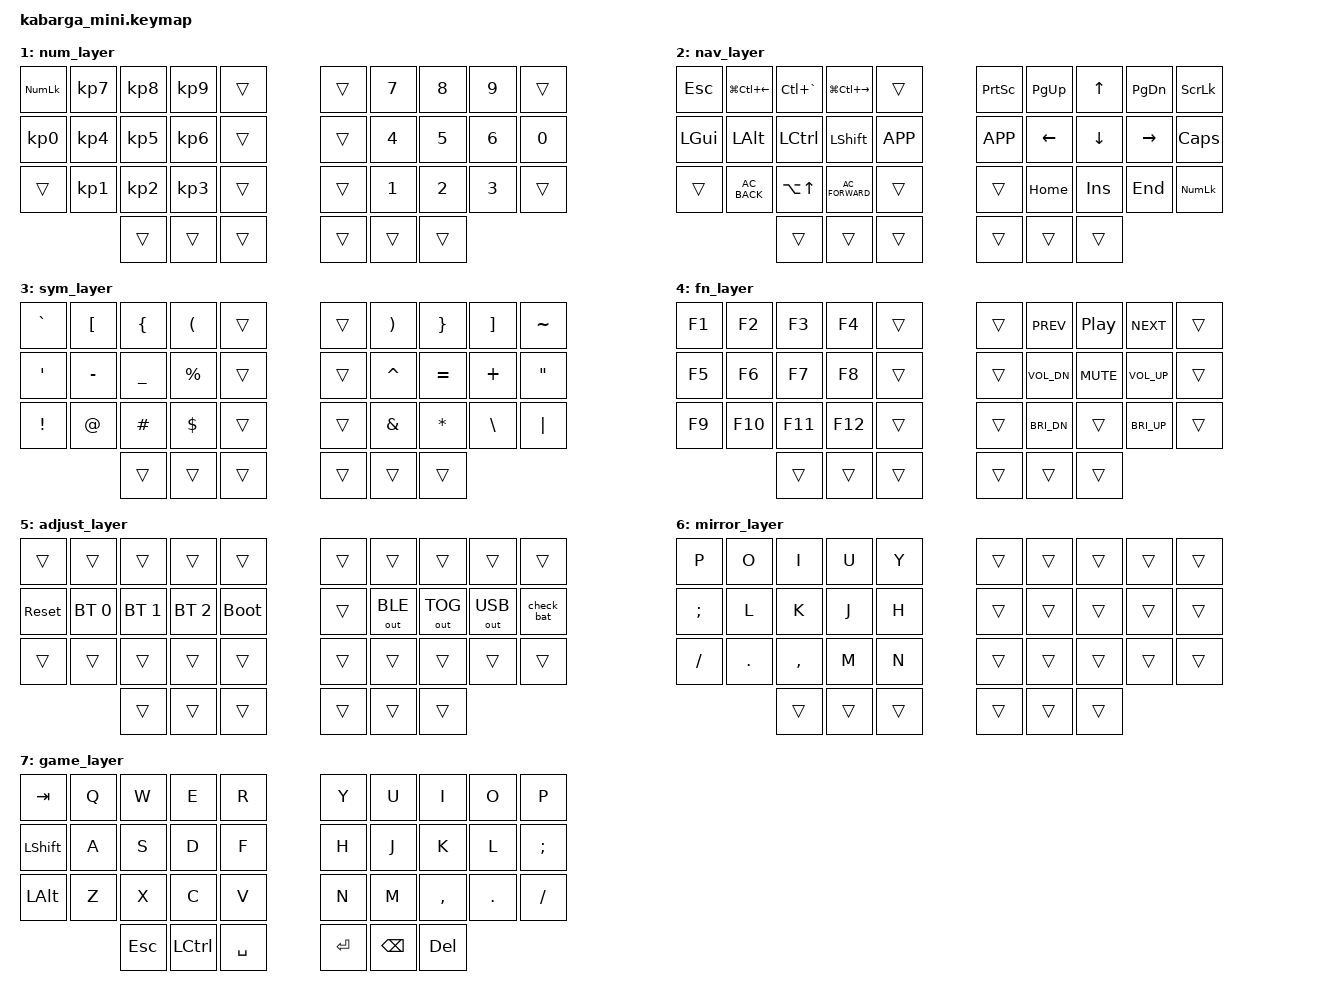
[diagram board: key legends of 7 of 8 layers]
/*
 * Copyright (c) 2020 The ZMK Contributors
 *
 * SPDX-License-Identifier: MIT
 */


#include <behaviors.dtsi>
#include <dt-bindings/zmk/keys.h>
#include <dt-bindings/zmk/bt.h>
#include <dt-bindings/zmk/outputs.h>
#include <dt-bindings/zmk/ext_power.h>
#include <dt-bindings/zmk/rgb.h>


#define HRML(k1,k2,k3,k4) &mt LGUI k1  &mt LALT k2  &mt LCTRL k3  &mt LSHFT k4
#define HRMR(k1,k2,k3,k4) &mt RSHFT k1  &mt RCTRL k2  &mt RALT k3  &mt RGUI k4
#define TERM &kp LC(GRAVE)
#define TASK_V &kp LG(TAB)
#define DESK_P &kp LG(LC(LEFT))
#define DESK_N &kp LG(LC(RIGHT))
#define COMBO(NAME, BINDINGS, KEYPOS, LAYERS) \
    combo_##NAME { \
        timeout-ms = <50>; \
        bindings = <BINDINGS>; \
        key-positions = <KEYPOS>; \
        layers = <LAYERS>; \
    };


&lt {
    flavor = "tap-preferred"; // balanced
    tapping-term-ms = <150>;
    quick-tap-ms = <200>;
};
&mt {
    flavor = "tap-preferred"; // balanced
    tapping-term-ms = <150>;
    quick-tap-ms = <200>;
};


/ {
    //╭──────┬──────┬──────┬──────┬──────╮   ╭──────┬──────┬──────┬──────┬──────╮
    //│  0   │  1   │  2   │  3   │  4   │   │  5   │  6   │  7   │  8   │  9   │
    //├──────┼──────┼──────┼──────┼──────┼───┼──────┼──────┼──────┼──────┼──────┤
    //│  10  │  11  │  12  │  13  │  14  │   │  15  │  16  │  17  │  18  │  19  │
    //├──────┼──────┼──────┼──────┼──────┤   ├──────┼──────┼──────┼──────┼──────┤
    //│  20  │  21  │  22  │  23  │  24  │   │  25  │  26  │  27  │  28  │  29  │
    //╰──────┴──────┼──────┼──────┼──────┼───┼──────┼──────┼──────┼──────┴──────╯
    //              |  30  |  31  |  32  |   |  33  |  34  |  35  |
    //              ╰──────┴──────┴──────╯   ╰──────┴──────┴──────╯

    combos {
        compatible = "zmk,combos";
            // main
        COMBO(enter,              &kp RET,          12 13,        0)
        COMBO(backspace,          &kp BSPC,         11 12,        0)
        COMBO(delete,             &kp DEL,          11 13,        0)
        COMBO(fn_layer,           &mo 4,            24 31,        0)
            // game
        COMBO(game,               &tog 7,            0 32,        0 7)
            // num
        COMBO(num_space_l,        &kp SPACE,        12 13,        1)
        COMBO(num_dot_l,          &kp DOT,          11 12,        1)
        COMBO(num_comma_l,        &kp COMMA,        11 13,        1)
        COMBO(num_space_r,        &kp SPACE,        16 17,        1)
        COMBO(num_dot_r,          &kp DOT,          17 18,        1)
        COMBO(num_comma_r,        &kp COMMA,        16 18,        1)
            // nav
        COMBO(nav_taskv,          TASK_V,            1  3,        2)
            // mirror
        COMBO(right_mirror,       &mo 6,            31 32,        0)
            // adjust
        COMBO(bluetooth_clear,    &bt BT_CLR,        10 14,        5)
    };


    conditional_layers {
        compatible = "zmk,conditional-layers";
        adjust_layer {
            if-layers = <2 3>;
            then-layer = <5>;
        };
    };


    keymap {
        compatible = "zmk,keymap";
        // - 0
        default_layer {
            bindings = <
        //╭──────────┬──────────┬──────────┬──────────┬──────────╮   ╭──────────┬──────────┬──────────┬──────────┬──────────╮
        //│  Q       │  W       │  E       │  R       │  T       │   │  Y       │  U       │  I       │  O       │  P       │
            &kp Q      &kp W      &kp E      &kp R      &kp T          &kp Y      &kp U      &kp I      &kp O      &kp P
        //├──────────┼──────────┼──────────┼──────────┼──────────┤   ├──────────┼──────────┼──────────┼──────────┼──────────┤
        //│  A       │  S       │  D       │  F       │  G       │   │  H       │  J       │  K       │  L       │  ;       │
             HRML(A,        S,         D,         F)     &kp G          &kp H      HRMR(J,        K,         L,        SEMI)
        //├──────────┼──────────┼──────────┼──────────┼──────────┤   ├──────────┼──────────┼──────────┼──────────┼──────────┤
        //│  Z       │  X       │  C       │  V       │  B       │   │  N       │  M       │ , <      │ . >      │ / ?      │
            &kp Z      &kp X      &kp C      &kp V      &kp B          &kp N      &kp M      &kp COMMA  &kp DOT    &kp FSLH
        //╰──────────┴──────────┼──────────┼──────────┼──────────┤   ├──────────┼──────────┼──────────┼──────────┴──────────╯
                                  &lt 4 ESC  &lt 1 TAB  &lt 2 SPACE    &lt 3 RET  &lt 4 BSPC &kp DEL
        //                      ╰──────────┴──────────┴──────────╯   ╰──────────┴──────────┴──────────╯
            >;
        };


        // - 1
        num_layer {
            bindings = <
        //╭──────────┬──────────┬──────────┬──────────┬──────────╮   ╭──────────┬──────────┬──────────┬──────────┬──────────╮
        //│  NLCK    │  7       │  8       │  9       │          │   │          │  7       │  8       │  9       │          │
            &kp KP_NUM &kp KP_N7  &kp KP_N8  &kp KP_N9  &trans         &trans     &kp N7     &kp N8     &kp N9     &trans
        //├──────────┼──────────┼──────────┼──────────┼──────────┤   ├──────────┼──────────┼──────────┼──────────┼──────────┤
        //│  0       │  4       │  5       │  6       │          │   │          │  4       │  5       │  6       │  0       │
            &kp KP_N0  &kp KP_N4  &kp KP_N5  &kp KP_N6  &trans         &trans     &kp N4     &kp N5     &kp N6     &kp N0
        //├──────────┼──────────┼──────────┼──────────┼──────────┤   ├──────────┼──────────┼──────────┼──────────┼──────────┤
        //│          │  1       │  2       │  3       │          │   │          │  1       │  2       │  3       │          │
            &trans     &kp KP_N1  &kp KP_N2  &kp KP_N3  &trans         &trans     &kp N1     &kp N2     &kp N3     &trans
        //╰──────────┴──────────┼──────────┼──────────┼──────────┤   ├──────────┼──────────┼──────────┼──────────┴──────────╯
                                  &trans     &trans     &trans         &trans     &trans     &trans
        //                      ╰──────────┴──────────┴──────────╯   ╰──────────┴──────────┴──────────╯
            >;
        };


        // - 2
        nav_layer {
            bindings = <
        //╭──────────┬──────────┬──────────┬──────────┬──────────╮   ╭──────────┬──────────┬──────────┬──────────┬──────────╮
        //│ ESC      │ DESK <   │ TERMINAL │ DESK >   │          │   │ PRNT SCR │ PG_UP    │ UP       │ PG_DOWN  │ S_LCOK   │
            &kp ESC    DESK_P     TERM       DESK_N     &trans         &kp PSCRN  &kp PG_UP  &kp UP     &kp PG_DN  &kp SLCK
        //├──────────┼──────────┼──────────┼──────────┼──────────┤   ├──────────┼──────────┼──────────┼──────────┼──────────┤
        //│ GUI      │ ALT      │ CTRL     │ SHIFT    │ APP      │   │ APP      │ LEFT     │ DOWN     │ RIGHT    │ C_LOCK   │
            &kp LGUI   &kp LALT   &kp LCTRL  &kp LSHFT  &kp K_APP      &kp K_APP  &kp LEFT   &kp DOWN   &kp RIGHT  &kp CLCK
        //├──────────┼──────────┼──────────┼──────────┼──────────┤   ├──────────┼──────────┼──────────┼──────────┼──────────┤
        //│          │ BACK     │ UP       │ FORWARD  │          │   │          │ HOME     │ INSERT   │ END      │ N_LOCK   │
            &trans     &kp C_AC_BACK  &kp LA(UP)  &kp C_AC_FORWARD &trans  &trans &kp HOME   &kp INS    &kp END   &kp KP_NLCK
        //╰──────────┴──────────┼──────────┼──────────┼──────────┤   ├──────────┼──────────┼──────────┼──────────┴──────────╯
                                  &trans     &trans     &trans         &trans     &trans     &trans
        //                      ╰──────────┴──────────┴──────────╯   ╰──────────┴──────────┴──────────╯
            >;
        };


        // - 3
        sym_layer {
            bindings = <
        //╭──────────┬──────────┬──────────┬──────────┬──────────╮   ╭──────────┬──────────┬──────────┬──────────┬──────────╮
        //│  `       │  [       │  {       │  (       │          │   │          │  )       │  }       │  ]       │  ~       │
            &kp GRAVE  &kp LBKT   &kp LBRC   &kp LPAR   &trans         &trans     &kp RPAR   &kp RBRC   &kp RBKT   &kp TILDE
        //├──────────┼──────────┼──────────┼──────────┼──────────┤   ├──────────┼──────────┼──────────┼──────────┼──────────┤
        //│  '       │  -       │  _       │  %       │          │   │          │  ^       │  =       │  +       │  "       │
            &kp SQT    &kp MINUS  &kp UNDER  &kp PRCNT  &trans         &trans     &kp CARET  &kp EQUAL  &kp PLUS   &kp DQT
        //├──────────┼──────────┼──────────┼──────────┼──────────┤   ├──────────┼──────────┼──────────┼──────────┼──────────┤
        //│  !       │  @       │  #       │  $       │          │   │          │  &       │  *       │  \       │  |       │
            &kp EXCL   &kp AT     &kp HASH   &kp DLLR   &trans         &trans     &kp AMPS   &kp ASTRK  &kp BSLH   &kp PIPE
        //╰──────────┴──────────┼──────────┼──────────┼──────────┤   ├──────────┼──────────┼──────────┼──────────┴──────────╯
                                  &trans     &trans     &trans         &trans     &trans     &trans
        //                      ╰──────────┴──────────┴──────────╯   ╰──────────┴──────────┴──────────╯
            >;
        };


        // - 4
        fn_layer {
            bindings = <
        //╭──────────┬──────────┬──────────┬──────────┬──────────╮   ╭──────────┬──────────┬──────────┬──────────┬──────────╮
        //│ F1       │ F2       │ F3       │ F4       │          │   │          │ <<<      │ P\P      │ >>>      │          │
            &kp F1     &kp F2     &kp F3     &kp F4     &trans         &trans     &kp C_PREV &kp C_PP   &kp C_NEXT &trans
        //├──────────┼──────────┼──────────┼──────────┼──────────┤   ├──────────┼──────────┼──────────┼──────────┼──────────┤
        //│ F4       │ F5       │ F6       │ F8       │          │   │          │ VOL-     │ MUTE     │ VOL+     │          │
            &kp F5     &kp F6     &kp F7     &kp F8     &trans         &trans     &kp C_VOL_DN &kp C_MUTE &kp C_VOL_UP &trans
        //├──────────┼──────────┼──────────┼──────────┼──────────┤   ├──────────┼──────────┼──────────┼──────────┼──────────┤
        //│ F9       │ F10      │ F11      │ F12      │          │   │          │ BRI-     │          │ BRI+     │          │
            &kp F9     &kp F10    &kp F11    &kp F12    &trans         &trans     &kp C_BRI_DN &trans   &kp C_BRI_UP &trans
        //╰──────────┴──────────┼──────────┼──────────┼──────────┤   ├──────────┼──────────┼──────────┼──────────┴──────────╯
                                  &trans     &trans     &trans         &trans     &trans     &trans
        //                      ╰──────────┴──────────┴──────────╯   ╰──────────┴──────────┴──────────╯
            >;
        };


        // - 5
        adjust_layer {
            bindings = <
        //╭──────────┬──────────┬──────────┬──────────┬──────────╮   ╭──────────┬──────────┬──────────┬──────────┬──────────╮
        //│          │          │          │          │          │   │          │          │          │          │          │
            &trans     &trans     &trans     &trans     &trans         &trans     &trans     &trans     &trans     &trans
        //├──────────┼──────────┼──────────┼──────────┼──────────┤   ├──────────┼──────────┼──────────┼──────────┼──────────┤
        //│ RESET    │ BT 0     │ BT 1     │ BT 2     │ BOOT     │   │          │ OUT BLE  │ OUT TOG  │ OUT USB  │ BAT CHCK │
            &sys_reset &bt BT_SEL 0 &bt BT_SEL 1 &bt BT_SEL 2 &bootloader &trans  &out OUT_BLE &out OUT_TOG &out OUT_USB &check_bat
        //├──────────┼──────────┼──────────┼──────────┼──────────┤   ├──────────┼──────────┼──────────┼──────────┼──────────┤
        //│          │          │          │          │          │   │          │          │          │          │          │
            &trans     &trans     &trans     &trans     &trans         &trans     &trans     &trans     &trans     &trans
        //╰──────────┴──────────┼──────────┼──────────┼──────────┤   ├──────────┼──────────┼──────────┼──────────┴──────────╯
                                  &trans     &trans     &trans         &trans     &trans     &trans
        //                      ╰──────────┴──────────┴──────────╯   ╰──────────┴──────────┴──────────╯
            >;
        };


        // - 6
        mirror_layer {
            bindings = <
        //╭──────────┬──────────┬──────────┬──────────┬──────────╮   ╭──────────┬──────────┬──────────┬──────────┬──────────╮
        //│  P       │  O       │  I       │  U       │  Y       │   │          │          │          │          │          │
            &kp P      &kp O      &kp I      &kp U      &kp Y          &trans     &trans     &trans     &trans     &trans
        //├──────────┼──────────┼──────────┼──────────┼──────────┤   ├──────────┼──────────┼──────────┼──────────┼──────────┤
        //│  ;       │  L       │  K       │  J       │  H       │   │          │          │          │          │          │
            &kp SEMI   &kp L      &kp K      &kp J      &kp H          &trans     &trans     &trans     &trans     &trans
        //├──────────┼──────────┼──────────┼──────────┼──────────┤   ├──────────┼──────────┼──────────┼──────────┼──────────┤
        //│  / ?     │ . >      │ , <      │  M       │  N       │   │          │          │          │          │          │
            &kp FSLH   &kp DOT    &kp COMMA  &kp M      &kp N          &trans     &trans     &trans     &trans     &trans
        //╰──────────┴──────────┼──────────┼──────────┼──────────┤   ├──────────┼──────────┼──────────┼──────────┴──────────╯
                                  &trans     &trans     &trans         &trans     &trans     &trans
        //                      ╰──────────┴──────────┴──────────╯   ╰──────────┴──────────┴──────────╯
            >;
        };


        // - 7
        game_layer {
            bindings = <
        //╭──────────┬──────────┬──────────┬──────────┬──────────╮   ╭──────────┬──────────┬──────────┬──────────┬──────────╮
        //│  TAB     │  Q       │  W       │  E       │  R       │   │  Y       │  U       │  I       │  O       │  P       │
            &kp TAB    &kp Q      &kp W      &kp E      &kp R          &kp Y      &kp U      &kp I      &kp O      &kp P
        //├──────────┼──────────┼──────────┼──────────┼──────────┤   ├──────────┼──────────┼──────────┼──────────┼──────────┤
        //│  SHIFT   │  A       │  S       │  D       │  F       │   │  H       │  J       │  K       │  L       │  ;       │
            &kp LSHFT  &kp A      &kp S      &kp D      &kp F          &kp H      &kp J      &kp K      &kp L      &kp SEMI
        //├──────────┼──────────┼──────────┼──────────┼──────────┤   ├──────────┼──────────┼──────────┼──────────┼──────────┤
        //│  ALT     │  Z       │  X       │  C       │  V       │   │  N       │  M       │  ,       │  .       │  /       │
            &kp LALT   &kp Z      &kp X      &kp C      &kp V          &kp N      &kp M      &kp COMMA  &kp DOT    &kp FSLH
        //╰──────────┴──────────┼──────────┼──────────┼──────────┤   ├──────────┼──────────┼──────────┼──────────┴──────────╯
                                  &kp ESC    &kp LCTRL  &kp SPACE      &kp RET    &kp BSPC   &kp DEL
        //                      ╰──────────┴──────────┴──────────╯   ╰──────────┴──────────┴──────────╯
            >;
        };

    };
};
